AUTOSAR XML (schema 314)
package /ComponentType
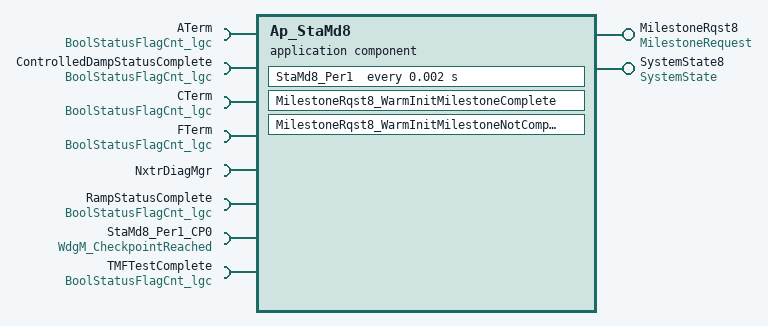
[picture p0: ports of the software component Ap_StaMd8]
  application software component type Ap_StaMd8
    provide port MilestoneRqst8: provided-interface=MilestoneRequest
      provided-com-specs:
        operation=WarmInitMilestoneComplete, queue-length=1
        operation=WarmInitMilestoneNotComplete, queue-length=1
    provide port SystemState8: mode-switch-com-spec{mode-group=Mode, queue-length=1}, provided-interface=SystemState
    8 x require port:
      ATerm: unqueued-receiver-com-spec{data-element=Cnt_lgc, init-value=D_TRUE_CNT_LGC}, required-interface=BoolStatusFlagCnt_lgc
      ControlledDampStatusComplete: unqueued-receiver-com-spec{data-element=Cnt_lgc, init-value=D_FALSE_CNT_LGC}, required-interface=BoolStatusFlagCnt_lgc
      CTerm: unqueued-receiver-com-spec{data-element=Cnt_lgc, init-value=D_FALSE_CNT_LGC}, required-interface=BoolStatusFlagCnt_lgc
      FTerm: unqueued-receiver-com-spec{data-element=Cnt_lgc, init-value=D_FALSE_CNT_LGC}, required-interface=BoolStatusFlagCnt_lgc
      NxtrDiagMgr: required-com-specs=[GetNTCActive, GetNTCFailed, GetNTCStatus, SetNTCStatus], required-interface=NxtrDiagMgr
      RampStatusComplete: unqueued-receiver-com-spec{data-element=Cnt_lgc, init-value=D_FALSE_CNT_LGC}, required-interface=BoolStatusFlagCnt_lgc
      StaMd8_Per1_CP0: client-com-spec=CheckpointReached, required-interface=WdgM_CheckpointReached
      TMFTestComplete: unqueued-receiver-com-spec{data-element=Cnt_lgc, init-value=D_FALSE_CNT_LGC}, required-interface=BoolStatusFlagCnt_lgc
  internal behavior Ap_StaMd8_InternalBehavior: component=Ap_StaMd8
    operation invoked event OIT_MilestoneRqst8_WarmInitMilestoneComplete_MilestoneRqst8_WarmInitMilestoneComplete: start-on-event=MilestoneRqst8_WarmInitMilestoneComplete, operation=MilestoneRqst8.WarmInitMilestoneComplete
    operation invoked event OIT_MilestoneRqst8_WarmInitMilestoneNotComplete_MilestoneRqst8_WarmInitMilestoneNotComplete: start-on-event=MilestoneRqst8_WarmInitMilestoneNotComplete, operation=MilestoneRqst8.WarmInitMilestoneNotComplete
    timing event TMT_StaMd8_Per1: start-on-event=StaMd8_Per1, period=0.002
    exclusive area StaMds8_MilestoneRqst_WARMINIT_ExclArea
    port-api-options:
      enable-take-address=false, indirect-api=false, port=ATerm
      enable-take-address=false, indirect-api=false, port=ControlledDampStatusComplete
      enable-take-address=false, indirect-api=false, port=CTerm
      enable-take-address=false, indirect-api=false, port=FTerm
      enable-take-address=false, indirect-api=false, port=MilestoneRqst8
      enable-take-address=false, indirect-api=false, port=NxtrDiagMgr
      enable-take-address=false, indirect-api=false, port=RampStatusComplete
      enable-take-address=false, indirect-api=false, port=StaMd8_Per1_CP0
      enable-take-address=false, indirect-api=false, port=SystemState8
      enable-take-address=false, indirect-api=false, port=TMFTestComplete
    runnable MilestoneRqst8_WarmInitMilestoneComplete: can-be-invoked-concurrently=true, can-enter-exclusive-area=StaMds8_MilestoneRqst_WARMINIT_ExclArea
    runnable MilestoneRqst8_WarmInitMilestoneNotComplete: can-be-invoked-concurrently=true, can-enter-exclusive-area=StaMds8_MilestoneRqst_WARMINIT_ExclArea
    runnable StaMd8_Per1
      6 x data read access:
        READ_ATerm_Cnt_lgc: data-element=ATerm.Cnt_lgc
        READ_ControlledDampStatusComplete_Cnt_lgc: data-element=ControlledDampStatusComplete.Cnt_lgc
        READ_CTerm_Cnt_lgc: data-element=CTerm.Cnt_lgc
        READ_FTerm_Cnt_lgc: data-element=FTerm.Cnt_lgc
        READ_RampStatusComplete_Cnt_lgc: data-element=RampStatusComplete.Cnt_lgc
        READ_TMFTestComplete_Cnt_lgc: data-element=TMFTestComplete.Cnt_lgc
      mode switch point SWITCH_SystemState8_Mode: mode-group=SystemState8.Mode
      sync call SC_NxtrDiagMgr_SetNTCStatus: operation=NxtrDiagMgr.SetNTCStatus, timeout=0
      sync call SC_StaMd8_Per1_CP0_CheckpointReached: operation=StaMd8_Per1_CP0.CheckpointReached, timeout=0
  swc implementation Ap_StaMd8_Implementation: behavior=Ap_StaMd8_InternalBehavior
    code-descriptors:
      code Code: type=SRC
